# STM32L452 register map
File version: 1.0
CPU: CM4 r0p1, little endian, MPU, FPU, 4 interrupt priority bits
Registers are 32-bit, read-write, reset 0x0 unless marked. A register's access mark holds for its fields unless they carry their own. Offsets are from the block's base; [hi:lo] are bit positions.

## COMP — Comparator
Base 0x40010200
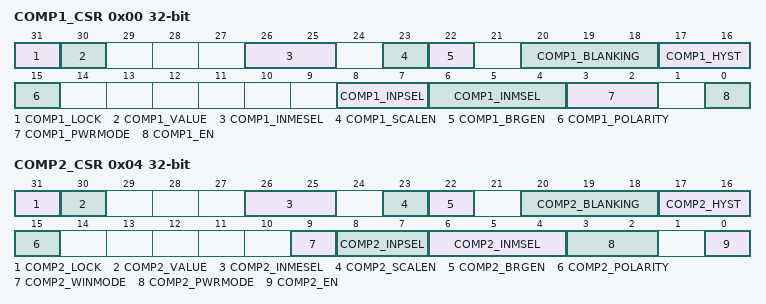
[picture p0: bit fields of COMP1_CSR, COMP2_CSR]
0x00 COMP1_CSR access per field — Comparator 1 control and status register
  [31] COMP1_LOCK wo — COMP1_CSR register lock bit
  [30] COMP1_VALUE ro — Comparator 1 output status bit
  [26:25] COMP1_INMESEL rw — comparator 1 input minus extended selection bits
  [23] COMP1_SCALEN rw — Voltage scaler enable bit
  [22] COMP1_BRGEN rw — Scaler bridge enable
  [20:18] COMP1_BLANKING rw — Comparator 1 blanking source selection bits
  [17:16] COMP1_HYST rw — Comparator 1 hysteresis selection bits
  [15] COMP1_POLARITY rw — Comparator 1 polarity selection bit
  [8:7] COMP1_INPSEL rw — Comparator1 input plus selection bit
  [6:4] COMP1_INMSEL rw — Comparator 1 Input Minus connection configuration bit
  [3:2] COMP1_PWRMODE rw — Power Mode of the comparator 1
  [0] COMP1_EN rw — Comparator 1 enable bit
0x04 COMP2_CSR access per field — Comparator 2 control and status register
  [31] COMP2_LOCK wo — COMP2_CSR register lock bit
  [30] COMP2_VALUE ro — Comparator 2 output status bit
  [26:25] COMP2_INMESEL rw — comparator 2 input minus extended selection bits
  [23] COMP2_SCALEN rw — Voltage scaler enable bit
  [22] COMP2_BRGEN rw — Scaler bridge enable
  [20:18] COMP2_BLANKING rw — Comparator 2 blanking source selection bits
  [17:16] COMP2_HYST rw — Comparator 2 hysteresis selection bits
  [15] COMP2_POLARITY rw — Comparator 2 polarity selection bit
  [9] COMP2_WINMODE rw — Windows mode selection bit
  [8:7] COMP2_INPSEL rw — Comparator 2 Input Plus connection configuration bit
  [6:4] COMP2_INMSEL rw — Comparator 2 Input Minus connection configuration bit
  [3:2] COMP2_PWRMODE rw — Power Mode of the comparator 2
  [0] COMP2_EN rw — Comparator 2 enable bit

## FIREWALL
Base 0x40011C00
0x00 CSSA — Code segment start address
  [23:8] ADD — code segment start address
0x04 CSL — Code segment length
  [21:8] LENG — code segment length
0x08 NVDSSA — Non-volatile data segment start address
  [23:8] ADD
0x0C NVDSL — Non-volatile data segment length
  [21:8] LENG
0x10 VDSSA — Volatile data segment start address
  [15:6] ADD
0x14 VDSL — Volatile data segment length
  [15:6] LENG — Non-volatile data segment length
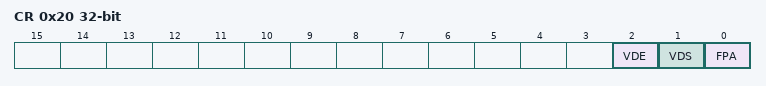
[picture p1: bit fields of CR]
0x20 CR — Configuration register
  [2] VDE — Volatile data execution
  [1] VDS — Volatile data shared
  [0] FPA — Firewall pre alarm

## FLASH
Base 0x40022000
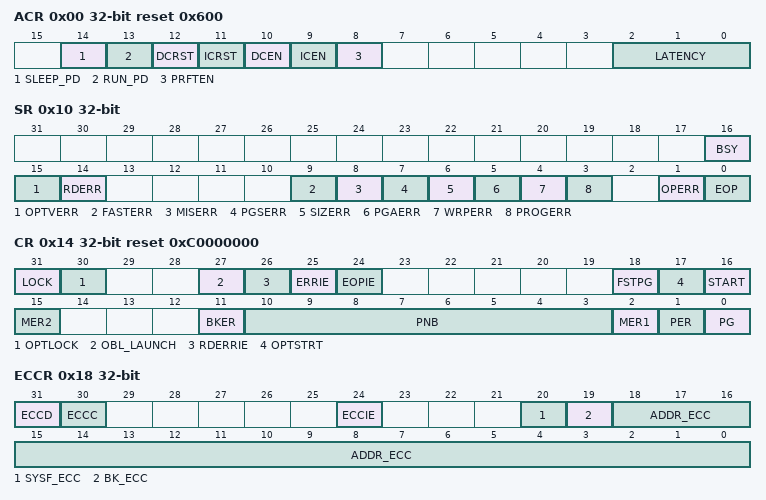
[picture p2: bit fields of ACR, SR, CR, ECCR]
0x00 ACR reset 0x600 — Access control register
  [14] SLEEP_PD — Flash Power-down mode during Low-power sleep mode
  [13] RUN_PD — Flash Power-down mode during Low-power run mode
  [12] DCRST — Data cache reset
  [11] ICRST — Instruction cache reset
  [10] DCEN — Data cache enable
  [9] ICEN — Instruction cache enable
  [8] PRFTEN — Prefetch enable
  [2:0] LATENCY
0x04 PDKEYR wo — Power down key register
  [31:0] PDKEYR — RUN_PD in FLASH_ACR key
0x08 KEYR wo — Flash key register
0x0C OPTKEYR wo — Option byte key register
  [31:0] OPTKEYR — Option byte key
0x10 SR access per field — Status register
  [16] BSY ro — Busy
  [15] OPTVERR rw — Option validity error
  [14] RDERR rw — PCROP read error
  [9] FASTERR rw — Fast programming error
  [8] MISERR rw — Fast programming data miss error
  [7] PGSERR rw — Programming sequence error
  [6] SIZERR rw — Size error
  [5] PGAERR rw — Programming alignment error
  [4] WRPERR rw — Write protected error
  [3] PROGERR rw — Programming error
  [1] OPERR rw — Operation error
  [0] EOP rw — End of operation
0x14 CR reset 0xC0000000 — Flash control register
  [31] LOCK — FLASH_CR Lock
  [30] OPTLOCK — Options Lock
  [27] OBL_LAUNCH — Force the option byte loading
  [26] RDERRIE — PCROP read error interrupt enable
  [25] ERRIE — Error interrupt enable
  [24] EOPIE — End of operation interrupt enable
  [18] FSTPG — Fast programming
  [17] OPTSTRT — Options modification start
  [16] START
  [15] MER2 — Bank 2 Mass erase
  [11] BKER — Bank erase
  [10:3] PNB — Page number
  [2] MER1 — Bank 1 Mass erase
  [1] PER — Page erase
  [0] PG — Programming
0x18 ECCR access per field — Flash ECC register
  [31] ECCD rw — ECC detection
  [30] ECCC rw — ECC correction
  [24] ECCIE rw — ECC correction interrupt enable
  [20] SYSF_ECC ro — System Flash ECC fail
  [19] BK_ECC ro — ECC fail bank
  [18:0] ADDR_ECC ro — ECC fail address
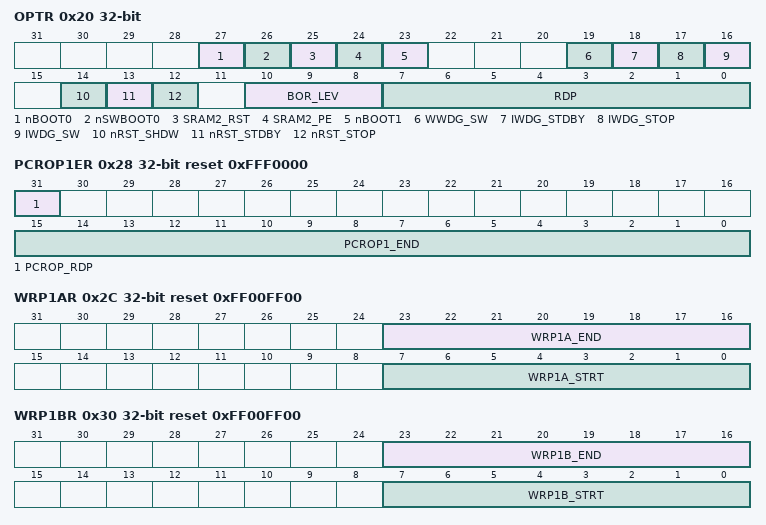
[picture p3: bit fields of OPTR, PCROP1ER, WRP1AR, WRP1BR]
0x20 OPTR — Flash option register
  [27] nBOOT0 — nBOOT0 option bit
  [26] nSWBOOT0 — Software BOOT0
  [25] SRAM2_RST — SRAM2 Erase when system reset
  [24] SRAM2_PE — SRAM2 parity check enable
  [23] nBOOT1 — Boot configuration
  [19] WWDG_SW — Window watchdog selection
  [18] IWDG_STDBY — Independent watchdog counter freeze in Standby mode
  [17] IWDG_STOP — Independent watchdog counter freeze in Stop mode
  [16] IWDG_SW — Independent watchdog selection
  [14] nRST_SHDW
  [13] nRST_STDBY
  [12] nRST_STOP
  [10:8] BOR_LEV — BOR reset Level
  [7:0] RDP — Read protection level
0x24 PCROP1SR reset 0xFFFF0000 — Flash Bank 1 PCROP Start address register
  [15:0] PCROP1_STRT — Bank 1 PCROP area start offset
0x28 PCROP1ER reset 0xFFF0000 — Flash Bank 1 PCROP End address register
  [31] PCROP_RDP — PCROP area preserved when RDP level decreased
  [15:0] PCROP1_END — Bank 1 PCROP area end offset
0x2C WRP1AR reset 0xFF00FF00 — Flash Bank 1 WRP area A address register
  [23:16] WRP1A_END — WRP first area A end offset
  [7:0] WRP1A_STRT — WRP first area A start offset
0x30 WRP1BR reset 0xFF00FF00 — Flash Bank 1 WRP area B address register
  [23:16] WRP1B_END — Bank 1 WRP second area B end offset
  [7:0] WRP1B_STRT — Bank 1 WRP second area B start offset

## Notices in the file
Copyright (c) 2024 STMicroelectronics.
SPDX-License-Identifier: Apache-2.0
Licensed under the Apache License, Version 2.0 (the "License");
you may not use this file except in compliance with the License.
You may obtain a copy of the License at
http://www.apache.org/licenses/LICENSE-2.0
Unless required by applicable law or agreed to in writing, software
distributed under the License is distributed on an "AS IS" BASIS,
WITHOUT WARRANTIES OR CONDITIONS OF ANY KIND, either express or implied.
See the License for the specific language governing permissions and
limitations under the License.
